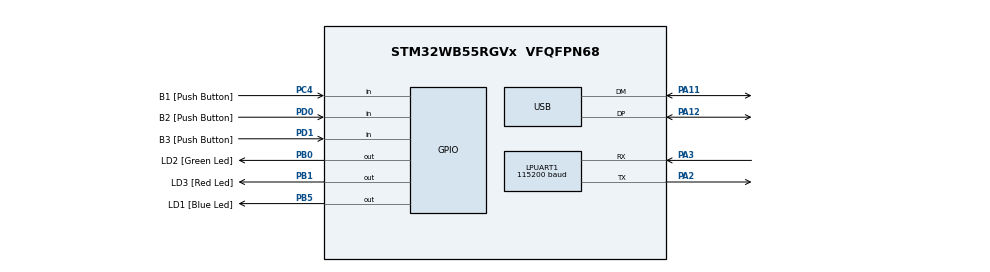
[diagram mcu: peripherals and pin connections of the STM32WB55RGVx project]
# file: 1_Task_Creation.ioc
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FREERTOS.INCLUDE_vTaskCleanUpResources=1
FREERTOS.Tasks01=defaultTask,24,128,StartDefaultTask,Default,NULL,Dynamic,NULL,NULL
FREERTOS.configUSE_NEWLIB_REENTRANT=1
LPUART1.BaudRate=115200
Mcu.Family=STM32WB
Mcu.Name=STM32WB55RGVx
Mcu.Package=VFQFPN68
NVIC.PriorityGroup=NVIC_PRIORITYGROUP_4
NVIC.TIM1_UP_TIM16_IRQn=true\:15\:0\:false\:false\:true\:false\:false\:true\:true
NVIC.TimeBase=TIM1_UP_TIM16_IRQn
NVIC.TimeBaseIP=TIM1
OSC_IN.Mode=HSE-External-Oscillator
OSC_IN.Signal=RCC_OSC_IN
OSC_OUT.Mode=HSE-External-Oscillator
OSC_OUT.Signal=RCC_OSC_OUT
PA11.Mode=Device
PA11.Signal=USB_DM
PA12.Mode=Device
PA12.Signal=USB_DP
PA13.GPIO_Label=JTMS
PA13.Mode=Serial_Wire
PA13.Signal=SYS_JTMS-SWDIO
PA14.GPIO_Label=JTCK
PA14.Mode=Serial_Wire
PA14.Signal=SYS_JTCK-SWCLK
PA2.Mode=Asynchronous
PA2.Signal=LPUART1_TX
PA3.Mode=Asynchronous
PA3.Signal=LPUART1_RX
PB0.GPIO_Label=LD2 [Green Led]
PB0.Signal=GPIO_Output
PB1.GPIO_Label=LD3 [Red Led]
PB1.Signal=GPIO_Output
PB3.GPIO_Label=JTDO
PB3.Signal=SYS_JTDO-SWO
PB5.GPIO_Label=LD1 [Blue Led]
PB5.Signal=GPIO_Output
PB6.GPIO_Label=STLINK_RX
PB6.GPIO_PuPd=GPIO_PULLUP
PB6.Signal=USART1_TX
PB7.GPIO_Label=STLINK_TX
PB7.GPIO_PuPd=GPIO_PULLUP
PB7.Signal=USART1_RX
PC13.Signal=SYS_WKUP2
PC14-OSC32_IN.Mode=LSE-External-Oscillator
PC14-OSC32_IN.Signal=RCC_OSC32_IN
PC15-OSC32_OUT.Mode=LSE-External-Oscillator
PC15-OSC32_OUT.Signal=RCC_OSC32_OUT
PC4.GPIO_Label=B1 [Push Button]
PC4.Signal=GPIO_Input
PD0.GPIO_Label=B2 [Push Button]
PD0.Signal=GPIO_Input
PD1.GPIO_Label=B3 [Push Button]
PD1.Signal=GPIO_Input
ProjectManager.HeapSize=0x200
ProjectManager.StackSize=0x400
ProjectManager.TargetToolchain=STM32CubeIDE
RCC.ADCFreq_Value=48000000
RCC.AHBFreq_Value=32000000
RCC.APB1Freq_Value=32000000
RCC.APB1TimFreq_Value=32000000
RCC.APB2Freq_Value=32000000
RCC.APB2TimFreq_Value=32000000
RCC.APB3Freq_Value=16000000
RCC.CortexFreq_Value=32000000
RCC.HCLKFreq_Value=32000000
RCC.HSE_VALUE=32000000
RCC.HSI48_VALUE=48000000
RCC.HSI_VALUE=16000000
RCC.PLLN=32
RCC.PLLSAI1N=24
RCC.SMPSCLockSelectionVirtual=RCC_SMPSCLKSOURCE_HSI
RCC.SMPSCLockSelectionVirtualVirtual=RCC_SMPSCLKSOURCE_HSI
RCC.SMPSDivider=1
RCC.SYSCLKFreq_VALUE=32000000
RCC.SYSCLKSource=RCC_SYSCLKSOURCE_HSE
RCC.USBFreq_Value=48000000
RCC.VCOOutputFreq_Value=128000000
VP_FREERTOS_VS_CMSIS_V2.Mode=CMSIS_V2
VP_SYS_VS_tim1.Mode=TIM1
VP_SYS_V_PVD_IN.Mode=Mode_PVD_Int
board=P-NUCLEO-WB55-NUCLEO

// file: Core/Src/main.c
#include "main.h"
#include "cmsis_os.h"
#include <stdio.h>

UART_HandleTypeDef hlpuart1;

PCD_HandleTypeDef hpcd_USB_FS;
void SystemClock_Config (void);
;
static void MX_GPIO_Init (void);
static void MX_LPUART1_UART_Init (void);
static void MX_USB_PCD_Init (void);

int __io_putchar (int ch);

void SenderTask(void *pvParameters);
void ReceiverTask(void *pvParameters);

typedef enum
{
	humidity_sensor,
	pressure_sensor
} DataSource_t;

typedef struct
{
	uint8_t ucValue;
	DataSource_t sDataSource;
} Data_t;

static const Data_t xStructToSend[ 2 ] =
		{
				{ 77, humidity_sensor },	// Used by humidity sensor
				{ 63, pressure_sensor }		// Used by pressure sensor
		};

Data_t xReceivedStructure;

TaskHandle_t hum_task_handle, press_task_handle, receiver_handle;

QueueHandle_t xQueue;

int main (void)
{

	HAL_Init ();
	SystemClock_Config ();
	MX_GPIO_Init ();
	MX_LPUART1_UART_Init ();
	MX_USB_PCD_Init ();

//	Create queue to hold a maximum of 3 structures.
	xQueue = xQueueCreate(3, sizeof(Data_t));

	xTaskCreate(ReceiverTask,
	            "Receiver Task",
	            100,
	            NULL,
	            1,
	            &receiver_handle);

	xTaskCreate(SenderTask,
	            "Humidity Sender Task",
	            100,
	            (void *)&(xStructToSend[0]),
	            2,
	            &hum_task_handle);

	xTaskCreate(SenderTask,
	            "Pressure Sender Task",
	            100,
	            (void *)&(xStructToSend[1]),
	            2,
	            &hum_task_handle);

	vTaskStartScheduler();

	while (1)
	{

	}

}

void SenderTask(void *pvParameters)
{
	BaseType_t qStatus;

	//	Enter blocked state for 200ms for space to become available in the queue each
	//	time the queue is full
	const TickType_t wait_time = pdMS_TO_TICKS(200);
	while(1)
	{
		qStatus = xQueueSend(xQueue, pvParameters, wait_time);
		if(qStatus != pdPASS)
		{
//			Do Something ...
			for(uint32_t i = 0; i < 100000; i++) {}
		}
	}

}

void ReceiverTask(void *pvParameters)
{
//	Data_t xReceivedStructure;

	BaseType_t qStatus;

	while(1)
	{
		qStatus = xQueueReceive(xQueue, &xReceivedStructure, 0);

		if(qStatus != pdPASS)
		{
			for(uint32_t i = 0; i < 100000; i++) {}
		}
		else {
			if(xReceivedStructure.sDataSource == humidity_sensor)
			{
				printf("Humidity sensor value = %d \n\r", xReceivedStructure.ucValue);
			}
			else
			{
				printf("Pressure sensor value = %d \n\r", xReceivedStructure.ucValue);
			}
		}
	}
}

int __io_putchar (int ch)
{
	HAL_UART_Transmit (&hlpuart1, (uint8_t*) &ch, 1, 0xFFFF);
	return ch;
}

void SystemClock_Config (void)
{
	RCC_OscInitTypeDef RCC_OscInitStruct =
		{ 0 };
	RCC_ClkInitTypeDef RCC_ClkInitStruct =
		{ 0 };

	/** Macro to configure the PLL multiplication factor
	 */
	__HAL_RCC_PLL_PLLM_CONFIG(RCC_PLLM_DIV1);

	/** Macro to configure the PLL clock source
	 */
	__HAL_RCC_PLL_PLLSOURCE_CONFIG(RCC_PLLSOURCE_MSI);

	/** Configure LSE Drive Capability
	 */
	HAL_PWR_EnableBkUpAccess ();
	__HAL_RCC_LSEDRIVE_CONFIG(RCC_LSEDRIVE_LOW);

	/** Configure the main internal regulator output voltage
	 */
	__HAL_PWR_VOLTAGESCALING_CONFIG(PWR_REGULATOR_VOLTAGE_SCALE1);

	/** Initializes the RCC Oscillators according to the specified parameters
	 * in the RCC_OscInitTypeDef structure.
	 */
	RCC_OscInitStruct.OscillatorType = RCC_OSCILLATORTYPE_HSI
	        | RCC_OSCILLATORTYPE_HSE | RCC_OSCILLATORTYPE_LSE
	        | RCC_OSCILLATORTYPE_MSI;
	RCC_OscInitStruct.HSEState = RCC_HSE_ON;
	RCC_OscInitStruct.LSEState = RCC_LSE_ON;
	RCC_OscInitStruct.HSIState = RCC_HSI_ON;
	RCC_OscInitStruct.MSIState = RCC_MSI_ON;
	RCC_OscInitStruct.HSICalibrationValue = RCC_HSICALIBRATION_DEFAULT;
	RCC_OscInitStruct.MSICalibrationValue = RCC_MSICALIBRATION_DEFAULT;
	RCC_OscInitStruct.MSIClockRange = RCC_MSIRANGE_6;
	RCC_OscInitStruct.PLL.PLLState = RCC_PLL_NONE;
	if (HAL_RCC_OscConfig (&RCC_OscInitStruct) != HAL_OK)
	{
		Error_Handler ();
	}

	/** Configure the SYSCLKSource, HCLK, PCLK1 and PCLK2 clocks dividers
	 */
	RCC_ClkInitStruct.ClockType = RCC_CLOCKTYPE_HCLK4 | RCC_CLOCKTYPE_HCLK2
	        | RCC_CLOCKTYPE_HCLK | RCC_CLOCKTYPE_SYSCLK | RCC_CLOCKTYPE_PCLK1
	        | RCC_CLOCKTYPE_PCLK2;
	RCC_ClkInitStruct.SYSCLKSource = RCC_SYSCLKSOURCE_HSE;
	RCC_ClkInitStruct.AHBCLKDivider = RCC_SYSCLK_DIV1;
	RCC_ClkInitStruct.APB1CLKDivider = RCC_HCLK_DIV1;
	RCC_ClkInitStruct.APB2CLKDivider = RCC_HCLK_DIV1;
	RCC_ClkInitStruct.AHBCLK2Divider = RCC_SYSCLK_DIV1;
	RCC_ClkInitStruct.AHBCLK4Divider = RCC_SYSCLK_DIV1;

	if (HAL_RCC_ClockConfig (&RCC_ClkInitStruct, FLASH_LATENCY_1) != HAL_OK)
	{
		Error_Handler ();
	}

	/** Enable MSI Auto calibration
	 */
	HAL_RCCEx_EnableMSIPLLMode ();
}

static void MX_LPUART1_UART_Init (void)
{

	hlpuart1.Instance = LPUART1;
	hlpuart1.Init.BaudRate = 115200;
	hlpuart1.Init.WordLength = UART_WORDLENGTH_8B;
	hlpuart1.Init.StopBits = UART_STOPBITS_1;
	hlpuart1.Init.Parity = UART_PARITY_NONE;
	hlpuart1.Init.Mode = UART_MODE_TX_RX;
	hlpuart1.Init.HwFlowCtl = UART_HWCONTROL_NONE;
	hlpuart1.Init.OneBitSampling = UART_ONE_BIT_SAMPLE_DISABLE;
	hlpuart1.Init.ClockPrescaler = UART_PRESCALER_DIV1;
	hlpuart1.AdvancedInit.AdvFeatureInit = UART_ADVFEATURE_NO_INIT;
	hlpuart1.FifoMode = UART_FIFOMODE_DISABLE;
	if (HAL_UART_Init (&hlpuart1) != HAL_OK)
	{
		Error_Handler ();
	}
	if (HAL_UARTEx_SetTxFifoThreshold (&hlpuart1, UART_TXFIFO_THRESHOLD_1_8)
	        != HAL_OK)
	{
		Error_Handler ();
	}
	if (HAL_UARTEx_SetRxFifoThreshold (&hlpuart1, UART_RXFIFO_THRESHOLD_1_8)
	        != HAL_OK)
	{
		Error_Handler ();
	}
	if (HAL_UARTEx_DisableFifoMode (&hlpuart1) != HAL_OK)
	{
		Error_Handler ();
	}

}

static void MX_USB_PCD_Init (void)
{

	hpcd_USB_FS.Instance = USB;
	hpcd_USB_FS.Init.dev_endpoints = 8;
	hpcd_USB_FS.Init.speed = PCD_SPEED_FULL;
	hpcd_USB_FS.Init.phy_itface = PCD_PHY_EMBEDDED;
	hpcd_USB_FS.Init.Sof_enable = DISABLE;
	hpcd_USB_FS.Init.low_power_enable = DISABLE;
	hpcd_USB_FS.Init.lpm_enable = DISABLE;
	hpcd_USB_FS.Init.battery_charging_enable = DISABLE;
	if (HAL_PCD_Init (&hpcd_USB_FS) != HAL_OK)
	{
		Error_Handler ();
	}

}

static void MX_GPIO_Init (void)
{
	GPIO_InitTypeDef GPIO_InitStruct =
		{ 0 };

	/* GPIO Ports Clock Enable */
	__HAL_RCC_GPIOC_CLK_ENABLE();
	__HAL_RCC_GPIOA_CLK_ENABLE();
	__HAL_RCC_GPIOB_CLK_ENABLE();
	__HAL_RCC_GPIOD_CLK_ENABLE();

	/*Configure GPIO pin Output Level */
	HAL_GPIO_WritePin (GPIOB, LD2_Pin | LD3_Pin | LD1_Pin, GPIO_PIN_RESET);

	/*Configure GPIO pin : B1_Pin */
	GPIO_InitStruct.Pin = B1_Pin;
	GPIO_InitStruct.Mode = GPIO_MODE_INPUT;
	GPIO_InitStruct.Pull = GPIO_NOPULL;
	HAL_GPIO_Init (B1_GPIO_Port, &GPIO_InitStruct);

	/*Configure GPIO pins : LD2_Pin LD3_Pin LD1_Pin */
	GPIO_InitStruct.Pin = LD2_Pin | LD3_Pin | LD1_Pin;
	GPIO_InitStruct.Mode = GPIO_MODE_OUTPUT_PP;
	GPIO_InitStruct.Pull = GPIO_NOPULL;
	GPIO_InitStruct.Speed = GPIO_SPEED_FREQ_LOW;
	HAL_GPIO_Init (GPIOB, &GPIO_InitStruct);

	/*Configure GPIO pins : B2_Pin B3_Pin */
	GPIO_InitStruct.Pin = B2_Pin | B3_Pin;
	GPIO_InitStruct.Mode = GPIO_MODE_INPUT;
	GPIO_InitStruct.Pull = GPIO_NOPULL;
	HAL_GPIO_Init (GPIOD, &GPIO_InitStruct);

	/*Configure GPIO pins : STLINK_RX_Pin STLINK_TX_Pin */
	GPIO_InitStruct.Pin = STLINK_RX_Pin | STLINK_TX_Pin;
	GPIO_InitStruct.Mode = GPIO_MODE_AF_PP;
	GPIO_InitStruct.Pull = GPIO_PULLUP;
	GPIO_InitStruct.Speed = GPIO_SPEED_FREQ_LOW;
	GPIO_InitStruct.Alternate = GPIO_AF7_USART1;
	HAL_GPIO_Init (GPIOB, &GPIO_InitStruct);

}

void HAL_TIM_PeriodElapsedCallback (TIM_HandleTypeDef *htim)
{
	if (htim->Instance == TIM1)
	{
		HAL_IncTick ();
	}
}

void Error_Handler (void)
{
	/* USER CODE BEGIN Error_Handler_Debug */
	/* User can add his own implementation to report the HAL error return state */
	__disable_irq ();
	while (1)
	{
	}
	/* USER CODE END Error_Handler_Debug */
}
